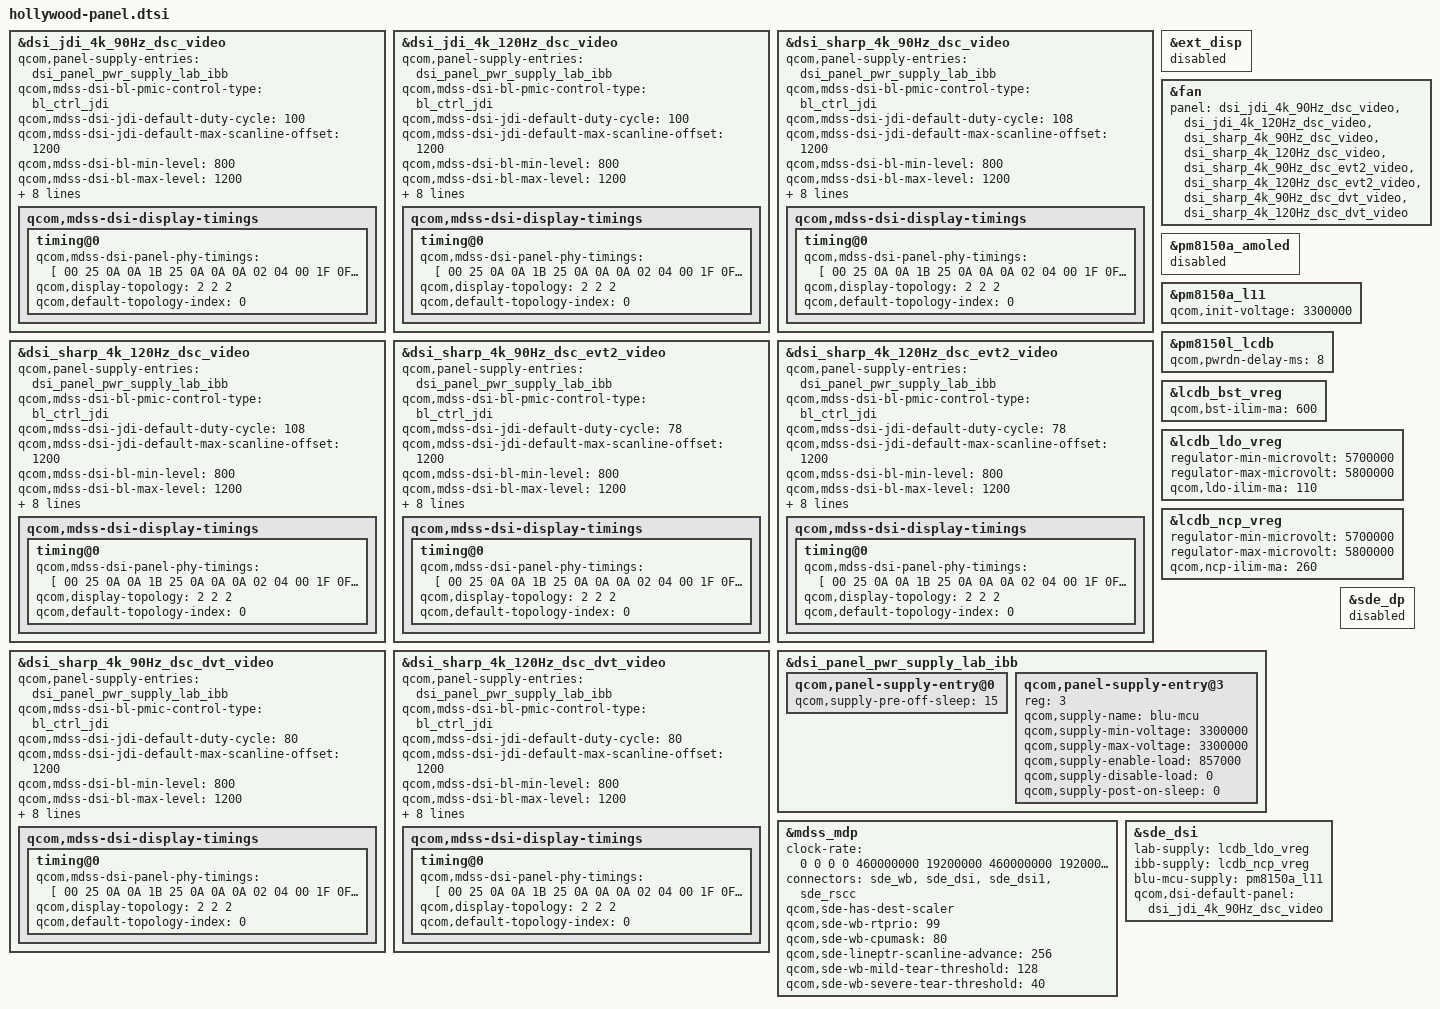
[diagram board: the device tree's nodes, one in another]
#include "dsi-panel-jdi-dsc-4k-90Hz-video.dtsi"
#include "dsi-panel-jdi-dsc-4k-120Hz-video.dtsi"
#include "dsi-panel-sharp-dsc-4k-90Hz-video.dtsi"
#include "dsi-panel-sharp-dsc-4k-120Hz-video.dtsi"
#include "dsi-panel-sharp-dsc-4k-90Hz-evt2-video.dtsi"
#include "dsi-panel-sharp-dsc-4k-120Hz-evt2-video.dtsi"
#include "dsi-panel-sharp-dsc-4k-90Hz-dvt-video.dtsi"
#include "dsi-panel-sharp-dsc-4k-120Hz-dvt-video.dtsi"

&dsi_jdi_4k_90Hz_dsc_video {
	qcom,panel-supply-entries = <&dsi_panel_pwr_supply_lab_ibb>;
	qcom,mdss-dsi-bl-pmic-control-type = "bl_ctrl_jdi";
	qcom,mdss-dsi-jdi-default-duty-cycle = <100>; /* 10.0% duty */
	qcom,mdss-dsi-jdi-default-max-scanline-offset = <1200>;
	qcom,mdss-dsi-bl-min-level = <800>;
	qcom,mdss-dsi-bl-max-level = <1200>;
	qcom,platform-en-gpio = <&tlmm 135 0>;
	qcom,platform-reset-gpio = <&tlmm 6 0>;
	qcom,mdss-dsi-reset-off-delay = <30>;
	qcom,mdss-dsi-t-clk-post = <0x0F>;
	qcom,mdss-dsi-t-clk-pre = <0x1F>;
	qcom,mdss-dsi-qsync-min-refresh-rate = <60>;
	qcom,dsi-select-clocks = "mux_byte_clk0", "mux_pixel_clk0";
	qcom,mdss-dsi-display-timings {
		timing@0{
			qcom,mdss-dsi-panel-phy-timings = [
				00 25 0A 0A 1B 25 0A
				0A 0A 02 04 00 1F 0F
			];
			qcom,display-topology = <2 2 2>;
			qcom,default-topology-index = <0>;
		};
	};
};

&dsi_jdi_4k_120Hz_dsc_video {
	qcom,panel-supply-entries = <&dsi_panel_pwr_supply_lab_ibb>;
	qcom,mdss-dsi-bl-pmic-control-type = "bl_ctrl_jdi";
	qcom,mdss-dsi-jdi-default-duty-cycle = <100>; /* 10.0% duty */
	qcom,mdss-dsi-jdi-default-max-scanline-offset = <1200>;
	qcom,mdss-dsi-bl-min-level = <800>;
	qcom,mdss-dsi-bl-max-level = <1200>;
	qcom,platform-en-gpio = <&tlmm 135 0>;
	qcom,platform-reset-gpio = <&tlmm 6 0>;
	qcom,mdss-dsi-reset-off-delay = <30>;
	qcom,mdss-dsi-t-clk-post = <0x0F>;
	qcom,mdss-dsi-t-clk-pre = <0x1F>;
	qcom,mdss-dsi-qsync-min-refresh-rate = <60>;
	qcom,dsi-select-clocks = "mux_byte_clk0", "mux_pixel_clk0";
	qcom,mdss-dsi-display-timings {
		timing@0{
			qcom,mdss-dsi-panel-phy-timings = [
				00 25 0A 0A 1B 25 0A
				0A 0A 02 04 00 1F 0F
			];
			qcom,display-topology = <2 2 2>;
			qcom,default-topology-index = <0>;
		};
	};
};

&dsi_sharp_4k_90Hz_dsc_video {
	qcom,panel-supply-entries = <&dsi_panel_pwr_supply_lab_ibb>;
	qcom,mdss-dsi-bl-pmic-control-type = "bl_ctrl_jdi";
	qcom,mdss-dsi-jdi-default-duty-cycle = <108>; /* 10.8% duty */
	qcom,mdss-dsi-jdi-default-max-scanline-offset = <1200>;
	qcom,mdss-dsi-bl-min-level = <800>;
	qcom,mdss-dsi-bl-max-level = <1200>;
	qcom,platform-en-gpio = <&tlmm 135 0>;
	qcom,platform-reset-gpio = <&tlmm 6 0>;
	qcom,mdss-dsi-reset-off-delay = <30>;
	qcom,mdss-dsi-t-clk-post = <0x0F>;
	qcom,mdss-dsi-t-clk-pre = <0x1F>;
	qcom,mdss-dsi-qsync-min-refresh-rate = <60>;
	qcom,dsi-select-clocks = "mux_byte_clk0", "mux_pixel_clk0";
	qcom,mdss-dsi-display-timings {
		timing@0{
			qcom,mdss-dsi-panel-phy-timings = [
				00 25 0A 0A 1B 25 0A
				0A 0A 02 04 00 1F 0F
			];
			qcom,display-topology = <2 2 2>;
			qcom,default-topology-index = <0>;
		};
	};
};

&dsi_sharp_4k_120Hz_dsc_video {
	qcom,panel-supply-entries = <&dsi_panel_pwr_supply_lab_ibb>;
	qcom,mdss-dsi-bl-pmic-control-type = "bl_ctrl_jdi";
	qcom,mdss-dsi-jdi-default-duty-cycle = <108>; /* 10.8% duty */
	qcom,mdss-dsi-jdi-default-max-scanline-offset = <1200>;
	qcom,mdss-dsi-bl-min-level = <800>;
	qcom,mdss-dsi-bl-max-level = <1200>;
	qcom,platform-en-gpio = <&tlmm 135 0>;
	qcom,platform-reset-gpio = <&tlmm 6 0>;
	qcom,mdss-dsi-reset-off-delay = <30>;
	qcom,mdss-dsi-t-clk-post = <0x0F>;
	qcom,mdss-dsi-t-clk-pre = <0x1F>;
	qcom,mdss-dsi-qsync-min-refresh-rate = <60>;
	qcom,dsi-select-clocks = "mux_byte_clk0", "mux_pixel_clk0";
	qcom,mdss-dsi-display-timings {
		timing@0{
			qcom,mdss-dsi-panel-phy-timings = [
				00 25 0A 0A 1B 25 0A
				0A 0A 02 04 00 1F 0F
			];
			qcom,display-topology = <2 2 2>;
			qcom,default-topology-index = <0>;
		};
	};
};

&dsi_sharp_4k_90Hz_dsc_evt2_video {
	qcom,panel-supply-entries = <&dsi_panel_pwr_supply_lab_ibb>;
	qcom,mdss-dsi-bl-pmic-control-type = "bl_ctrl_jdi";
	qcom,mdss-dsi-jdi-default-duty-cycle = <78>; /* 7.8% duty */
	qcom,mdss-dsi-jdi-default-max-scanline-offset = <1200>;
	qcom,mdss-dsi-bl-min-level = <800>;
	qcom,mdss-dsi-bl-max-level = <1200>;
	qcom,platform-en-gpio = <&tlmm 135 0>;
	qcom,platform-reset-gpio = <&tlmm 6 0>;
	qcom,mdss-dsi-reset-off-delay = <30>;
	qcom,mdss-dsi-t-clk-post = <0x0F>;
	qcom,mdss-dsi-t-clk-pre = <0x1F>;
	qcom,mdss-dsi-qsync-min-refresh-rate = <60>;
	qcom,dsi-select-clocks = "mux_byte_clk0", "mux_pixel_clk0";
	qcom,mdss-dsi-display-timings {
		timing@0{
			qcom,mdss-dsi-panel-phy-timings = [
				00 25 0A 0A 1B 25 0A
				0A 0A 02 04 00 1F 0F
			];
			qcom,display-topology = <2 2 2>;
			qcom,default-topology-index = <0>;
		};
	};
};

&dsi_sharp_4k_120Hz_dsc_evt2_video {
	qcom,panel-supply-entries = <&dsi_panel_pwr_supply_lab_ibb>;
	qcom,mdss-dsi-bl-pmic-control-type = "bl_ctrl_jdi";
	qcom,mdss-dsi-jdi-default-duty-cycle = <78>; /* 7.8% duty */
	qcom,mdss-dsi-jdi-default-max-scanline-offset = <1200>;
	qcom,mdss-dsi-bl-min-level = <800>;
	qcom,mdss-dsi-bl-max-level = <1200>;
	qcom,platform-en-gpio = <&tlmm 135 0>;
	qcom,platform-reset-gpio = <&tlmm 6 0>;
	qcom,mdss-dsi-reset-off-delay = <30>;
	qcom,mdss-dsi-t-clk-post = <0x0F>;
	qcom,mdss-dsi-t-clk-pre = <0x1F>;
	qcom,mdss-dsi-qsync-min-refresh-rate = <60>;
	qcom,dsi-select-clocks = "mux_byte_clk0", "mux_pixel_clk0";
	qcom,mdss-dsi-display-timings {
		timing@0{
			qcom,mdss-dsi-panel-phy-timings = [
				00 25 0A 0A 1B 25 0A
				0A 0A 02 04 00 1F 0F
			];
			qcom,display-topology = <2 2 2>;
			qcom,default-topology-index = <0>;
		};
	};
};

&dsi_sharp_4k_90Hz_dsc_dvt_video {
	qcom,panel-supply-entries = <&dsi_panel_pwr_supply_lab_ibb>;
	qcom,mdss-dsi-bl-pmic-control-type = "bl_ctrl_jdi";
	qcom,mdss-dsi-jdi-default-duty-cycle = <80>; /* 8.0% duty */
	qcom,mdss-dsi-jdi-default-max-scanline-offset = <1200>;
	qcom,mdss-dsi-bl-min-level = <800>;
	qcom,mdss-dsi-bl-max-level = <1200>;
	qcom,platform-en-gpio = <&tlmm 135 0>;
	qcom,platform-reset-gpio = <&tlmm 6 0>;
	qcom,mdss-dsi-reset-off-delay = <30>;
	qcom,mdss-dsi-t-clk-post = <0x0F>;
	qcom,mdss-dsi-t-clk-pre = <0x1F>;
	qcom,mdss-dsi-qsync-min-refresh-rate = <60>;
	qcom,dsi-select-clocks = "mux_byte_clk0", "mux_pixel_clk0";
	qcom,mdss-dsi-display-timings {
		timing@0{
			qcom,mdss-dsi-panel-phy-timings = [
				00 25 0A 0A 1B 25 0A
				0A 0A 02 04 00 1F 0F
			];
			qcom,display-topology = <2 2 2>;
			qcom,default-topology-index = <0>;
		};
	};
};

&dsi_sharp_4k_120Hz_dsc_dvt_video {
	qcom,panel-supply-entries = <&dsi_panel_pwr_supply_lab_ibb>;
	qcom,mdss-dsi-bl-pmic-control-type = "bl_ctrl_jdi";
	qcom,mdss-dsi-jdi-default-duty-cycle = <80>; /* 8.0% duty */
	qcom,mdss-dsi-jdi-default-max-scanline-offset = <1200>;
	qcom,mdss-dsi-bl-min-level = <800>;
	qcom,mdss-dsi-bl-max-level = <1200>;
	qcom,platform-en-gpio = <&tlmm 135 0>;
	qcom,platform-reset-gpio = <&tlmm 6 0>;
	qcom,mdss-dsi-reset-off-delay = <30>;
	qcom,mdss-dsi-t-clk-post = <0x0F>;
	qcom,mdss-dsi-t-clk-pre = <0x1F>;
	qcom,mdss-dsi-qsync-min-refresh-rate = <60>;
	qcom,dsi-select-clocks = "mux_byte_clk0", "mux_pixel_clk0";
	qcom,mdss-dsi-display-timings {
		timing@0{
			qcom,mdss-dsi-panel-phy-timings = [
				00 25 0A 0A 1B 25 0A
				0A 0A 02 04 00 1F 0F
			];
			qcom,display-topology = <2 2 2>;
			qcom,default-topology-index = <0>;
		};
	};
};

&ext_disp {
	status = "disabled";
};

&fan {
	panel = <&dsi_jdi_4k_90Hz_dsc_video
		&dsi_jdi_4k_120Hz_dsc_video
		&dsi_sharp_4k_90Hz_dsc_video
		&dsi_sharp_4k_120Hz_dsc_video
		&dsi_sharp_4k_90Hz_dsc_evt2_video
		&dsi_sharp_4k_120Hz_dsc_evt2_video
		&dsi_sharp_4k_90Hz_dsc_dvt_video
		&dsi_sharp_4k_120Hz_dsc_dvt_video>;
};

&pm8150a_amoled {
	status = "disabled";
};

&pm8150a_l11 {
	qcom,init-voltage = <3300000>;
};

&pm8150l_lcdb {
	status = "ok";
	qcom,pwrdn-delay-ms = <8>;
};

&lcdb_bst_vreg {
	qcom,bst-ilim-ma = <600>;
};

&lcdb_ldo_vreg {
	regulator-min-microvolt = <5700000>;
	regulator-max-microvolt = <5800000>;
	qcom,ldo-ilim-ma = <110>;
};

&lcdb_ncp_vreg {
	regulator-min-microvolt = <5700000>;
	regulator-max-microvolt = <5800000>;
	qcom,ncp-ilim-ma = <260>;
};

&dsi_panel_pwr_supply_lab_ibb {
	qcom,panel-supply-entry@0 {
		qcom,supply-pre-off-sleep = <15>;
	};

	qcom,panel-supply-entry@3 {
		reg = <3>;
		qcom,supply-name = "blu-mcu";
		qcom,supply-min-voltage = <3300000>;
		qcom,supply-max-voltage = <3300000>;
		qcom,supply-enable-load = <857000>;
		qcom,supply-disable-load = <0>;
		qcom,supply-post-on-sleep = <0>;
	};
};

&mdss_mdp {
	/* set mdp clk rate to max for Olivia panels */
	clock-rate = <0 0 0 0 460000000 19200000 460000000 19200000>;
	connectors = <&sde_wb &sde_dsi &sde_dsi1 &sde_rscc>;
	qcom,sde-has-dest-scaler;
	qcom,sde-wb-rtprio = <99>;
	qcom,sde-wb-cpumask = "80"; /* CPU7 */
	qcom,sde-lineptr-scanline-advance = <256>;
	qcom,sde-wb-mild-tear-threshold = <128>;
	qcom,sde-wb-severe-tear-threshold = <40>;
};

&sde_dsi {
	lab-supply = <&lcdb_ldo_vreg>;
	ibb-supply = <&lcdb_ncp_vreg>;
	blu-mcu-supply = <&pm8150a_l11>;
	qcom,dsi-default-panel = <&dsi_jdi_4k_90Hz_dsc_video>;
};

&sde_dp {
	status = "disabled";
};
